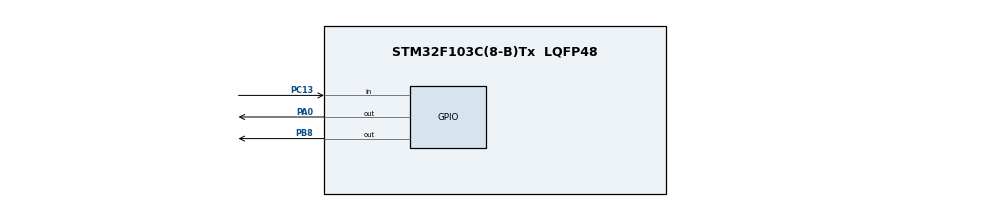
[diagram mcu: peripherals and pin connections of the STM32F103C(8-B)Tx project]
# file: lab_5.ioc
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FREERTOS.Tasks01=defaultTask,24,128,StartDefaultTask,Default,NULL,Dynamic,NULL,NULL
Mcu.Family=STM32F1
Mcu.Name=STM32F103C(8-B)Tx
Mcu.Package=LQFP48
NVIC.PriorityGroup=NVIC_PRIORITYGROUP_4
NVIC.TIM2_IRQn=true\:0\:0\:false\:false\:true\:false\:false\:true
NVIC.TimeBase=TIM2_IRQn
NVIC.TimeBaseIP=TIM2
PA0-WKUP.Signal=GPIO_Output
PA13.Mode=Serial_Wire
PA13.Signal=SYS_JTMS-SWDIO
PA14.Mode=Serial_Wire
PA14.Signal=SYS_JTCK-SWCLK
PB8.Signal=GPIO_Output
PC13-TAMPER-RTC.GPIO_PuPd=GPIO_PULLUP
PC13-TAMPER-RTC.Signal=GPIO_Input
ProjectManager.HeapSize=0x200
ProjectManager.StackSize=0x400
ProjectManager.TargetToolchain=MDK-ARM V5.27
RCC.APB1Freq_Value=8000000
RCC.APB2Freq_Value=8000000
VP_FREERTOS_VS_CMSIS_V2.Mode=CMSIS_V2
VP_SYS_VS_tim2.Mode=TIM2
board=custom

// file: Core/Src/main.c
/*Yukhymchuk Anastasiia, IT-81, Lab5*/
/* USER CODE BEGIN Header */
/**
  ******************************************************************************
  * @file           : main.c
  * @brief          : Main program body
  ******************************************************************************
  * @attention
  *
  * <h2><center>&copy; Copyright (c) 2021 STMicroelectronics.
  * All rights reserved.</center></h2>
  *
  * This software component is licensed by ST under Ultimate Liberty license
  * SLA0044, the "License"; You may not use this file except in compliance with
  * the License. You may obtain a copy of the License at:
  *                             www.st.com/SLA0044
  *
  ******************************************************************************
  */
/* USER CODE END Header */
#include "main.h"
#include "cmsis_os.h"

/* USER CODE BEGIN PD */
#define TRUE 0x01
#define FALSE 0x00
#define BTN_CLICKED_FLAG_1 0x01U
#define BTN_CLICKED_FLAG_2 0x02U
/* USER CODE END PD */

/* Definitions for defaultTask */
osThreadId_t defaultTaskHandle;
const osThreadAttr_t defaultTask_attributes = {
  .name = "defaultTask",
  .priority = (osPriority_t) osPriorityNormal,
  .stack_size = 128 * 4
};
/* USER CODE BEGIN PV */
volatile uint32_t ticks_delay;
osThreadId_t idThread1, idThread2, idBtnThread;
osEventFlagsId_t event_id;
/* USER CODE END PV */

void SystemClock_Config(void);
static void MX_GPIO_Init(void);
void StartDefaultTask(void *argument);

char checkButtonClick(uint32_t pin);
/* USER CODE BEGIN PFP */
void PWM(uint16_t dutyCycle, uint16_t period, GPIO_TypeDef* port, uint16_t pin);

void pwm_1(void* argument);
void pwm_2(void* argument);
void btn_thread(void* argument);
/* USER CODE END PFP */

int main(void)
{

  /* MCU Configuration--------------------------------------------------------*/

  /* Reset of all peripherals, Initializes the Flash interface and the Systick. */
  HAL_Init();

  /* Configure the system clock */
  SystemClock_Config();

  /* Initialize all configured peripherals */
  MX_GPIO_Init();

  /* Init scheduler */
  osKernelInitialize();

  /* Create the thread(s) */
  /* creation of defaultTask */
  defaultTaskHandle = osThreadNew(StartDefaultTask, NULL, &defaultTask_attributes);

  /* USER CODE BEGIN RTOS_THREADS */
  idThread1 = osThreadNew(pwm_1, NULL, NULL);
	idThread2 = osThreadNew(pwm_2, NULL, NULL);
	idBtnThread = osThreadNew(btn_thread, NULL, NULL);
  /* USER CODE END RTOS_THREADS */

  /* USER CODE BEGIN RTOS_EVENTS */
  event_id = osEventFlagsNew(NULL);
  /* USER CODE END RTOS_EVENTS */

  /* Start scheduler */
  osKernelStart();

  /* We should never get here as control is now taken by the scheduler */
  /* Infinite loop */
  while (1)
  {

  }
}

void SystemClock_Config(void)
{
  RCC_OscInitTypeDef RCC_OscInitStruct = {0};
  RCC_ClkInitTypeDef RCC_ClkInitStruct = {0};

  /** Initializes the RCC Oscillators according to the specified parameters
  * in the RCC_OscInitTypeDef structure.
  */
  RCC_OscInitStruct.OscillatorType = RCC_OSCILLATORTYPE_HSI;
  RCC_OscInitStruct.HSIState = RCC_HSI_ON;
  RCC_OscInitStruct.HSICalibrationValue = RCC_HSICALIBRATION_DEFAULT;
  RCC_OscInitStruct.PLL.PLLState = RCC_PLL_NONE;
  if (HAL_RCC_OscConfig(&RCC_OscInitStruct) != HAL_OK)
  {
    Error_Handler();
  }
  /** Initializes the CPU, AHB and APB buses clocks
  */
  RCC_ClkInitStruct.ClockType = RCC_CLOCKTYPE_HCLK|RCC_CLOCKTYPE_SYSCLK
                              |RCC_CLOCKTYPE_PCLK1|RCC_CLOCKTYPE_PCLK2;
  RCC_ClkInitStruct.SYSCLKSource = RCC_SYSCLKSOURCE_HSI;
  RCC_ClkInitStruct.AHBCLKDivider = RCC_SYSCLK_DIV1;
  RCC_ClkInitStruct.APB1CLKDivider = RCC_HCLK_DIV1;
  RCC_ClkInitStruct.APB2CLKDivider = RCC_HCLK_DIV1;

  if (HAL_RCC_ClockConfig(&RCC_ClkInitStruct, FLASH_LATENCY_0) != HAL_OK)
  {
    Error_Handler();
  }
}

static void MX_GPIO_Init(void)
{
  GPIO_InitTypeDef GPIO_InitStruct = {0};

  /* GPIO Ports Clock Enable */
  __HAL_RCC_GPIOC_CLK_ENABLE();
  __HAL_RCC_GPIOA_CLK_ENABLE();
  __HAL_RCC_GPIOB_CLK_ENABLE();

  /*Configure GPIO pin Output Level */
  HAL_GPIO_WritePin(GPIOA, GPIO_PIN_0, GPIO_PIN_RESET);

  /*Configure GPIO pin Output Level */
  HAL_GPIO_WritePin(GPIOB, GPIO_PIN_8, GPIO_PIN_RESET);

  /*Configure GPIO pin : PC13 */
  GPIO_InitStruct.Pin = GPIO_PIN_13;
  GPIO_InitStruct.Mode = GPIO_MODE_INPUT;
  GPIO_InitStruct.Pull = GPIO_PULLUP;
  HAL_GPIO_Init(GPIOC, &GPIO_InitStruct);

  /*Configure GPIO pin : PA0 */
  GPIO_InitStruct.Pin = GPIO_PIN_0;
  GPIO_InitStruct.Mode = GPIO_MODE_OUTPUT_PP;
  GPIO_InitStruct.Pull = GPIO_NOPULL;
  GPIO_InitStruct.Speed = GPIO_SPEED_FREQ_LOW;
  HAL_GPIO_Init(GPIOA, &GPIO_InitStruct);

  /*Configure GPIO pin : PB8 */
  GPIO_InitStruct.Pin = GPIO_PIN_8;
  GPIO_InitStruct.Mode = GPIO_MODE_OUTPUT_PP;
  GPIO_InitStruct.Pull = GPIO_NOPULL;
  GPIO_InitStruct.Speed = GPIO_SPEED_FREQ_LOW;
  HAL_GPIO_Init(GPIOB, &GPIO_InitStruct);

}

/* USER CODE BEGIN 4 */
void PWM(uint16_t dutyCycle, uint16_t period, GPIO_TypeDef* port, uint16_t pin)
{
	HAL_GPIO_WritePin(port, pin, GPIO_PIN_SET);
	osDelay(dutyCycle);
	HAL_GPIO_WritePin(port, pin, GPIO_PIN_RESET);
	osDelay(period - dutyCycle);
}

void pwm_1(void* argument){
	uint16_t period = 30;
	uint16_t width = 10;
	uint32_t flags;

	while(1){
		PWM(width, period, GPIOA, GPIO_PIN_0);

		flags = osEventFlagsGet(event_id);
		if (flags & BTN_CLICKED_FLAG_1){
			if(period * 2 <= 500) {
				period *= 2;
				width *= 2;
			}
			osEventFlagsClear(event_id, BTN_CLICKED_FLAG_1);
		}
	}
}

void pwm_2(void* argument){
	uint16_t period = 30;
	uint16_t width = 15;
	uint32_t flags;

	while(1){
		PWM(width, period, GPIOB, GPIO_PIN_8);

		flags = osEventFlagsGet(event_id);
		if (flags & BTN_CLICKED_FLAG_2){
			if(width / 2 >= 1) {
				period /= 2;
				width /= 2;
			}
			osEventFlagsClear(event_id, BTN_CLICKED_FLAG_2);
		}
	}
}

void btn_thread(void* argument){
	char isClicked;

	while(1){
		isClicked = checkButtonClick(GPIOC->IDR & GPIO_IDR_IDR13);
		if (isClicked){
			osEventFlagsSet(event_id, BTN_CLICKED_FLAG_1);
			osEventFlagsSet(event_id, BTN_CLICKED_FLAG_2);
			osDelay(1000);
		}
	}
}

char checkButtonClick(uint32_t pin)
{
	if (!pin){
		osDelay(20);
		if (!pin)
			return TRUE;
	}

	return FALSE;
}
/* USER CODE END 4 */

void StartDefaultTask(void *argument)
{
  for(;;)
  {
    osDelay(1);
  }
}

 /**
  * @brief  Period elapsed callback in non blocking mode
  * @note   This function is called  when TIM2 interrupt took place, inside
  * HAL_TIM_IRQHandler(). It makes a direct call to HAL_IncTick() to increment
  * a global variable "uwTick" used as application time base.
  * @param  htim : TIM handle
  * @retval None
  */
void HAL_TIM_PeriodElapsedCallback(TIM_HandleTypeDef *htim)
{
  if (htim->Instance == TIM2) {
    HAL_IncTick();
  }
}

void Error_Handler(void)
{
  __disable_irq();
  while (1)
  {
  }
}

/************************ (C) COPYRIGHT STMicroelectronics *****END OF FILE****/
